# STM32L412 register map
File version: 1.9
CPU: CM4 r0p1, little endian, MPU, FPU, 4 interrupt priority bits
Registers are 32-bit, read-write, reset 0x0 unless marked. A register's access mark holds for its fields unless they carry their own. Offsets are from the block's base; [hi:lo] are bit positions; 'fields as' and 'values as' point back to an identical list.

## ADC_Common — ADC common registers
Base 0x50040300
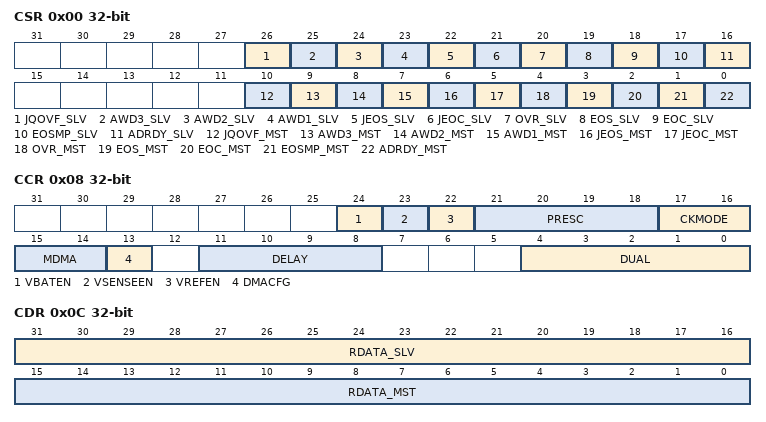
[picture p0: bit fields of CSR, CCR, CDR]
0x00 CSR ro — ADC common status register
  [26] JQOVF_SLV — Injected Context Queue Overflow flag of the slave ADC
    0=NoOverflow (No injected context queue overflow has occurred); 1=Overflow (Injected context queue overflow has occurred)
  [25] AWD3_SLV — Analog watchdog 3 flag of the slave ADC
    0=NoEvent (No analog watchdog event occurred); 1=Event (Analog watchdog event occurred)
  [24] AWD2_SLV — Analog watchdog 2 flag of the slave ADC
    values as AWD3_SLV
  [23] AWD1_SLV — Analog watchdog 1 flag of the slave ADC
    values as AWD3_SLV
  [22] JEOS_SLV — End of injected sequence flag of the slave ADC
    0=NotComplete (Injected sequence is not complete); 1=Complete (Injected sequence complete)
  [21] JEOC_SLV — End of injected conversion flag of the slave ADC
    0=NotComplete (Injected conversion is not complete); 1=Complete (Injected conversion complete)
  [20] OVR_SLV — Overrun flag of the slave ADC
    0=No overrun occurred; 1=Overrun occurred
  [19] EOS_SLV — End of regular sequence flag of the slave ADC
    0=NotComplete (Regular sequence is not complete); 1=Complete (Regular sequence complete)
  [18] EOC_SLV — End of regular conversion flag of the slave ADC
    0=NotComplete (Regular conversion is not complete); 1=Complete (Regular conversion complete)
  [17] EOSMP_SLV — End of Sampling phase flag of the slave ADC
    0=NotEnded (End of sampling phase no yet reached); 1=Ended (End of sampling phase reached)
  [16] ADRDY_SLV — Slave ADC ready
    0=NotReady (ADC is not ready to start conversion); 1=Ready (ADC is ready to start conversion)
  [10] JQOVF_MST — Injected Context Queue Overflow flag of the master ADC
    values as JQOVF_SLV
  [9] AWD3_MST — Analog watchdog 3 flag of the master ADC
    values as AWD3_SLV
  [8] AWD2_MST — Analog watchdog 2 flag of the master ADC
    values as AWD3_SLV
  [7] AWD1_MST — Analog watchdog 1 flag of the master ADC
    values as AWD3_SLV
  [6] JEOS_MST — End of injected sequence flag of the master ADC
    values as JEOS_SLV
  [5] JEOC_MST — End of injected conversion flag of the master ADC
    values as JEOC_SLV
  [4] OVR_MST — Overrun flag of the master ADC
    0=No overrun occurred; 1=Overrun occurred
  [3] EOS_MST — End of regular sequence flag of the master ADC
    values as EOS_SLV
  [2] EOC_MST — End of regular conversion flag of the master ADC
    values as EOC_SLV
  [1] EOSMP_MST — End of Sampling phase flag of the master ADC
    values as EOSMP_SLV
  [0] ADRDY_MST — master ADC ready
    values as ADRDY_SLV
0x08 CCR — ADC common control register
  [24] VBATEN — VBAT selection
    0=Disabled (The selected ADC channel disabled); 1=Enabled (The selected ADC channel enabled)
  [23] VSENSEEN — Temperature sensor selection
    values as VBATEN
  [22] VREFEN — Vrefint enable
    0=Disabled (V_REFINT channel disabled); 1=Enabled (V_REFINT channel enabled)
  [21:18] PRESC — ADC prescaler
    0=Div1 (Input ADC clock not divided); 1=Div2 (Input ADC clock divided by 2); 2=Div4 (Input ADC clock divided by 4); 3=Div6 (Input ADC clock divided by 6); 4=Div8 (Input ADC clock divided by 8); 5=Div10 (Input ADC clock divided by 10); 6=Div12 (Input ADC clock divided by 12); 7=Div16 (Input ADC clock divided by 16); 8=Div32 (Input ADC clock divided by 32); 9=Div64 (Input ADC clock divided by 64); 10=Div128 (Input ADC clock divided by 128); 11=Div256 (Input ADC clock divided by 256)
  [17:16] CKMODE — ADC clock mode
    0=Asynchronous (Use Kernel Clock adc_ker_ck_input divided by PRESC. Asynchronous to AHB clock); 1=SyncDiv1 (Use AHB clock rcc_hclk3. In this case rcc_hclk must equal sys_d1cpre_ck); 2=SyncDiv2 (Use AHB clock rcc_hclk3 divided by 2); 3=SyncDiv4 (Use AHB clock rcc_hclk3 divided by 4)
  [15:14] MDMA — Direct memory access mode for dual ADC mode
    0=Disabled (MDMA mode disabled); 1=Interleaved (Enable dual interleaved mode to output to the master channel of DFSDM interface both Master and the Slave result (16-bit data width)); 2=Bits12_10 (MDMA mode enabled for 12 and 10-bit resolution); 3=Bits8_6 (MDMA mode enabled for 8 and 6-bit resolution)
  [13] DMACFG — DMA configuration (for dual ADC mode)
    0=OneShotMode (DMA One Shot mode selected); 1=CircularMode (DMA Circular mode selected)
  [11:8] DELAY — Delay between 2 sampling phases
  [4:0] DUAL — Dual ADC mode selection
    0=Independent mode; 1=DualRJ (Dual, combined regular simultaneous + injected simultaneous mode); 2=DualRA (Dual, combined regular simultaneous + alternate trigger mode); 3=DualIJ (Dual, combined interleaved mode + injected simultaneous mode); 5=DualJ (Dual, injected simultaneous mode only); 6=Dual, regular simultaneous mode only; 7=Dual, interleaved mode only; 9=Dual, alternate trigger mode only
0x0C CDR ro — ADC common regular data register for dual mode
  [31:16] RDATA_SLV — Regular data of the slave ADC
  [15:0] RDATA_MST — Regular data of the master ADC
